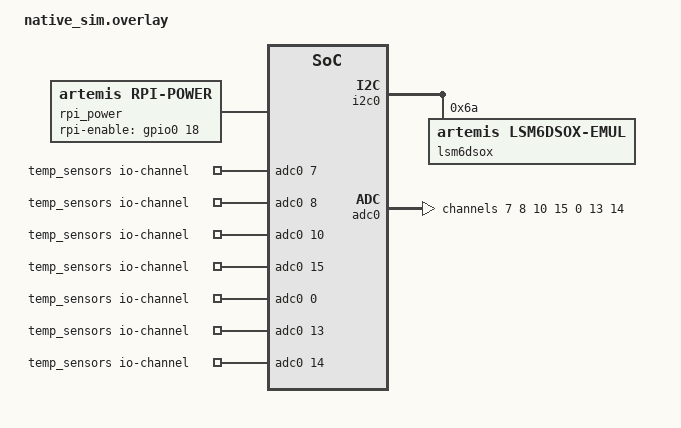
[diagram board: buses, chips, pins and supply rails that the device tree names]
#include <zephyr/dt-bindings/adc/adc.h>
#include <zephyr/dt-bindings/gpio/gpio.h>
/ {
    aliases {
        ground-uart = &uart_ground; pc-uart = &uart_pc; gps-uart = &uart_gps;
        pdu-uart = &uart_pdu; radio-uart = &uart_radio; power-uart = &uart_power;
        imu-bus = &i2c0;
    };
    rpi_power: rpi_power { compatible = "artemis,rpi-power"; rpi-enable-gpios = <&gpio0 18 GPIO_ACTIVE_HIGH>; };
    temp_sensors: zephyr,user { io-channels = <&adc0 7>, <&adc0 8>, <&adc0 10>, <&adc0 15>, <&adc0 0>, <&adc0 13>, <&adc0 14>; };
    uart_ground: uart_ground { compatible = "zephyr,native-tty-uart"; status = "okay"; current-speed = <115200>; serial-port = "/run/twin/ground.tty"; };
    uart_pc: uart_pc { compatible = "zephyr,native-tty-uart"; status = "okay"; current-speed = <115200>; serial-port = "/run/twin/pc.tty"; };
    uart_gps: uart_gps { compatible = "zephyr,native-tty-uart"; status = "okay"; current-speed = <9600>; serial-port = "/run/twin/gps.tty"; };
    uart_pdu: uart_pdu { compatible = "zephyr,native-tty-uart"; status = "okay"; current-speed = <9600>; serial-port = "/run/twin/pdu.tty"; };
    uart_radio: uart_radio { compatible = "zephyr,native-tty-uart"; status = "okay"; current-speed = <115200>; serial-port = "/run/twin/radio.tty"; };
    uart_power: uart_power { compatible = "zephyr,native-tty-uart"; status = "okay"; current-speed = <115200>; serial-port = "/run/twin/power.tty"; };
};
&i2c0 {
    status = "okay";
    lsm6dsox: lsm6dsox@6a { compatible = "artemis,lsm6dsox-emul"; reg = <0x6a>; };
};
&adc0 {
    status = "okay"; nchannels = <16>; ref-internal-mv = <3300>;
    #address-cells = <1>; #size-cells = <0>;
    channel@7 { reg = <7>; zephyr,gain = "ADC_GAIN_1"; zephyr,reference = "ADC_REF_INTERNAL"; zephyr,acquisition-time = <ADC_ACQ_TIME_DEFAULT>; zephyr,resolution = <12>; };
    channel@8 { reg = <8>; zephyr,gain = "ADC_GAIN_1"; zephyr,reference = "ADC_REF_INTERNAL"; zephyr,acquisition-time = <ADC_ACQ_TIME_DEFAULT>; zephyr,resolution = <12>; };
    channel@a { reg = <10>; zephyr,gain = "ADC_GAIN_1"; zephyr,reference = "ADC_REF_INTERNAL"; zephyr,acquisition-time = <ADC_ACQ_TIME_DEFAULT>; zephyr,resolution = <12>; };
    channel@f { reg = <15>; zephyr,gain = "ADC_GAIN_1"; zephyr,reference = "ADC_REF_INTERNAL"; zephyr,acquisition-time = <ADC_ACQ_TIME_DEFAULT>; zephyr,resolution = <12>; };
    channel@0 { reg = <0>; zephyr,gain = "ADC_GAIN_1"; zephyr,reference = "ADC_REF_INTERNAL"; zephyr,acquisition-time = <ADC_ACQ_TIME_DEFAULT>; zephyr,resolution = <12>; };
    channel@d { reg = <13>; zephyr,gain = "ADC_GAIN_1"; zephyr,reference = "ADC_REF_INTERNAL"; zephyr,acquisition-time = <ADC_ACQ_TIME_DEFAULT>; zephyr,resolution = <12>; };
    channel@e { reg = <14>; zephyr,gain = "ADC_GAIN_1"; zephyr,reference = "ADC_REF_INTERNAL"; zephyr,acquisition-time = <ADC_ACQ_TIME_DEFAULT>; zephyr,resolution = <12>; };
};
